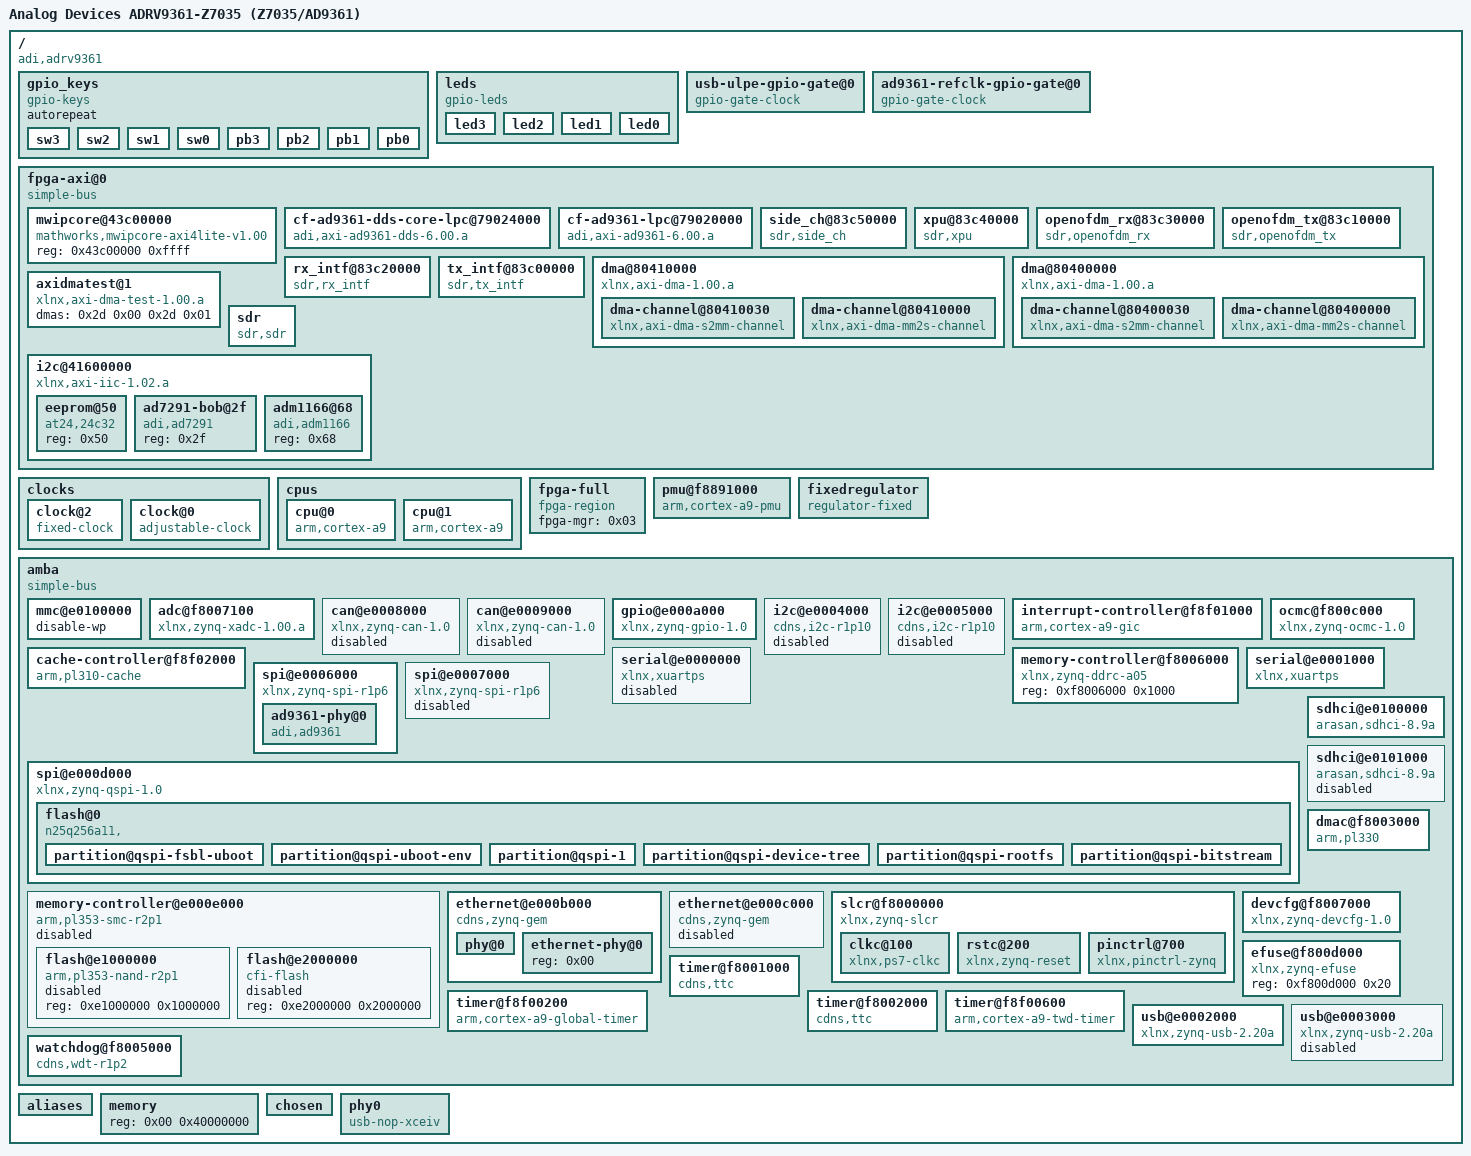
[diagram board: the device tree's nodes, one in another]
/dts-v1/;

/ {
	interrupt-parent = <0x04>;
	#address-cells = <0x01>;
	#size-cells = <0x01>;
	compatible = "adi,adrv9361\0xlnx,zynq-7000";
	model = "Analog Devices ADRV9361-Z7035 (Z7035/AD9361)";

	gpio_keys {
		autorepeat;
		#size-cells = <0x00>;
		#address-cells = <0x01>;
		compatible = "gpio-keys";

		sw3 {
			gpios = <0x0f 0x41 0x00>;
			linux,code = <0x03>;
			linux,input-type = <0x05>;
			label = "SW3";
		};

		sw2 {
			gpios = <0x0f 0x40 0x00>;
			linux,code = <0x02>;
			linux,input-type = <0x05>;
			label = "SW2";
		};

		sw1 {
			gpios = <0x0f 0x3f 0x00>;
			linux,code = <0x01>;
			linux,input-type = <0x05>;
			label = "SW1";
		};

		sw0 {
			gpios = <0x0f 0x3e 0x00>;
			linux,code = <0x00>;
			linux,input-type = <0x05>;
			label = "SW0";
		};

		pb3 {
			gpios = <0x0f 0x39 0x00>;
			linux,code = <0x6c>;
			label = "Down";
		};

		pb2 {
			gpios = <0x0f 0x38 0x00>;
			linux,code = <0x67>;
			label = "Up";
		};

		pb1 {
			gpios = <0x0f 0x37 0x00>;
			linux,code = <0x6a>;
			label = "Right";
		};

		pb0 {
			gpios = <0x0f 0x36 0x00>;
			linux,code = <0x69>;
			label = "Left";
		};
	};

	leds {
		compatible = "gpio-leds";

		led3 {
			gpios = <0x0f 0x3d 0x00>;
			label = "led3:green";
		};

		led2 {
			gpios = <0x0f 0x3c 0x00>;
			label = "led2:green";
		};

		led1 {
			gpios = <0x0f 0x3b 0x00>;
			label = "led1:green";
		};

		led0 {
			gpios = <0x0f 0x3a 0x00>;
			label = "led0:green";
		};
	};

	usb-ulpe-gpio-gate@0 {
		enable-gpios = <0x0f 0x09 0x01>;
		clocks = <0x32>;
		compatible = "gpio-gate-clock";
		#clock-cells = <0x00>;
	};

	ad9361-refclk-gpio-gate@0 {
		phandle = <0x30>;
		clock-output-names = "ad9361_ext_refclk";
		clk-set-rate-parent-enable;
		enable-gpios = <0x0f 0x69 0x00>;
		clocks = <0x31>;
		compatible = "gpio-gate-clock";
		#clock-cells = <0x00>;
	};

	fpga-axi@0 {
		ranges;
		#size-cells = <0x01>;
		#address-cells = <0x01>;
		compatible = "simple-bus";

		mwipcore@43c00000 {
			reg = <0x43c00000 0xffff>;
			compatible = "mathworks,mwipcore-axi4lite-v1.00";
		};

		cf-ad9361-dds-core-lpc@79024000 {
			clock-names = "sampl_clk";
			clocks = <0x2f 0x0d>;
			reg = <0x79024000 0x1000>;
			compatible = "adi,axi-ad9361-dds-6.00.a";
		};

		cf-ad9361-lpc@79020000 {
			spibus-connected = <0x2f>;
			reg = <0x79020000 0x6000>;
			compatible = "adi,axi-ad9361-6.00.a";
		};

		side_ch@83c50000 {
			phandle = <0x3a>;
			dma-names = "rx_dma_mm2s\0tx_dma_s2mm";
			dmas = <0x2d 0x00 0x2e 0x01>;
			reg = <0x83c50000 0x10000>;
			compatible = "sdr,side_ch";
			clocks = <0x2c 0x11>;
			clock-names = "s00_axi_aclk";
		};

		xpu@83c40000 {
			phandle = <0x39>;
			reg = <0x83c40000 0x10000>;
			compatible = "sdr,xpu";
			clocks = <0x2c 0x11>;
			clock-names = "s00_axi_aclk";
		};

		openofdm_rx@83c30000 {
			phandle = <0x38>;
			reg = <0x83c30000 0x10000>;
			compatible = "sdr,openofdm_rx";
			clocks = <0x2c 0x11>;
			clock-names = "clk";
		};

		openofdm_tx@83c10000 {
			phandle = <0x37>;
			reg = <0x83c10000 0x10000>;
			compatible = "sdr,openofdm_tx";
			clocks = <0x2c 0x11>;
			clock-names = "clk";
		};

		rx_intf@83c20000 {
			phandle = <0x36>;
			xlnx,s00-axi-data-width = <0x20>;
			xlnx,s00-axi-addr-width = <0x07>;
			reg = <0x83c20000 0x10000>;
			interrupts = <0x00 0x1d 0x01 0x00 0x1e 0x01>;
			interrupt-parent = <0x04>;
			interrupt-names = "not_valid_anymore\0rx_pkt_intr";
			compatible = "sdr,rx_intf";
			clocks = <0x2c 0x11 0x2c 0x11>;
			clock-names = "s00_axi_aclk\0m00_axis_aclk";
		};

		tx_intf@83c00000 {
			phandle = <0x35>;
			xlnx,s00-axi-data-width = <0x20>;
			xlnx,s00-axi-addr-width = <0x07>;
			reg = <0x83c00000 0x10000>;
			interrupts = <0x00 0x22 0x01>;
			interrupt-parent = <0x04>;
			interrupt-names = "tx_itrpt";
			compatible = "sdr,tx_intf";
			clocks = <0x2c 0x11 0x2c 0x11>;
			clock-names = "s00_axi_aclk\0s00_axis_aclk";
		};

		dma@80410000 {
			phandle = <0x2d>;
			xlnx,sg-length-width = <0x0e>;
			xlnx,include-sg;
			xlnx,addrwidth = <0x20>;
			reg = <0x80410000 0x10000>;
			interrupts = <0x00 0x1f 0x04 0x00 0x20 0x04>;
			interrupt-parent = <0x04>;
			interrupt-names = "mm2s_introut\0s2mm_introut";
			compatible = "xlnx,axi-dma-1.00.a";
			clocks = <0x2c 0x11 0x2c 0x11 0x2c 0x11 0x2c 0x11>;
			clock-names = "s_axi_lite_aclk\0m_axi_sg_aclk\0m_axi_mm2s_aclk\0m_axi_s2mm_aclk";
			#dma-cells = <0x01>;

			dma-channel@80410030 {
				xlnx,device-id = <0x01>;
				xlnx,datawidth = <0x40>;
				interrupts = <0x00 0x20 0x04>;
				dma-channels = <0x01>;
				compatible = "xlnx,axi-dma-s2mm-channel";
			};

			dma-channel@80410000 {
				xlnx,device-id = <0x01>;
				xlnx,datawidth = <0x40>;
				interrupts = <0x00 0x1f 0x04>;
				dma-channels = <0x01>;
				compatible = "xlnx,axi-dma-mm2s-channel";
			};
		};

		dma@80400000 {
			phandle = <0x2e>;
			xlnx,sg-length-width = <0x0e>;
			xlnx,include-sg;
			xlnx,addrwidth = <0x20>;
			reg = <0x80400000 0x10000>;
			interrupts = <0x00 0x23 0x04 0x00 0x24 0x04>;
			interrupt-parent = <0x04>;
			interrupt-names = "mm2s_introut\0s2mm_introut";
			compatible = "xlnx,axi-dma-1.00.a";
			clocks = <0x2c 0x11 0x2c 0x11 0x2c 0x11 0x2c 0x11>;
			clock-names = "s_axi_lite_aclk\0m_axi_sg_aclk\0m_axi_mm2s_aclk\0m_axi_s2mm_aclk";
			#dma-cells = <0x01>;

			dma-channel@80400030 {
				xlnx,device-id = <0x00>;
				xlnx,datawidth = <0x40>;
				interrupts = <0x00 0x24 0x04>;
				dma-channels = <0x01>;
				compatible = "xlnx,axi-dma-s2mm-channel";
			};

			dma-channel@80400000 {
				xlnx,device-id = <0x00>;
				xlnx,datawidth = <0x40>;
				interrupts = <0x00 0x23 0x04>;
				dma-channels = <0x01>;
				compatible = "xlnx,axi-dma-mm2s-channel";
			};
		};

		axidmatest@1 {
			phandle = <0x34>;
			dma-names = "axidma0\0axidma1";
			dmas = <0x2d 0x00 0x2d 0x01>;
			compatible = "xlnx,axi-dma-test-1.00.a";
		};

		sdr {
			phandle = <0x33>;
			interrupts = <0x00 0x1d 0x01 0x00 0x1e 0x01 0x00 0x21 0x01 0x00 0x22 0x01>;
			interrupt-parent = <0x04>;
			interrupt-names = "not_valid_anymore\0rx_pkt_intr\0tx_itrpt";
			dma-names = "rx_dma_s2mm\0tx_dma_mm2s";
			dmas = <0x2d 0x01 0x2e 0x00>;
			compatible = "sdr,sdr";
		};

		i2c@41600000 {
			#size-cells = <0x00>;
			#address-cells = <0x01>;
			clock-names = "pclk";
			clocks = <0x2c 0x0f>;
			interrupts = <0x00 0x3a 0x04>;
			interrupt-parent = <0x04>;
			reg = <0x41600000 0x10000>;
			compatible = "xlnx,axi-iic-1.02.a\0xlnx,xps-iic-2.00.a";

			eeprom@50 {
				reg = <0x50>;
				compatible = "at24,24c32";
			};

			ad7291-bob@2f {
				reg = <0x2f>;
				compatible = "adi,ad7291";
			};

			adm1166@68 {
				reg = <0x68>;
				compatible = "adi,adm1166";
			};
		};
	};

	clocks {

		clock@2 {
			phandle = <0x32>;
			clock-output-names = "24MHz";
			clock-frequency = <0x16e3600>;
			compatible = "fixed-clock";
			#clock-cells = <0x00>;
		};

		clock@0 {
			phandle = <0x31>;
			clock-output-names = "XO_40MHz";
			clock-accuracy = <0x30d40>;
			clock-frequency = <0x2625a00>;
			compatible = "adjustable-clock";
			#clock-cells = <0x00>;
		};
	};

	cpus {
		#address-cells = <0x01>;
		#size-cells = <0x00>;

		cpu@0 {
			compatible = "arm,cortex-a9";
			device_type = "cpu";
			reg = <0x00>;
			clocks = <0x01 0x03>;
			clock-latency = <0x3e8>;
			cpu0-supply = <0x02>;
			operating-points = <0xa2c2b 0xf4240 0x51616 0xf4240>;
			phandle = <0x08>;
		};

		cpu@1 {
			compatible = "arm,cortex-a9";
			device_type = "cpu";
			reg = <0x01>;
			clocks = <0x01 0x03>;
			phandle = <0x09>;
		};
	};

	fpga-full {
		compatible = "fpga-region";
		fpga-mgr = <0x03>;
		#address-cells = <0x01>;
		#size-cells = <0x01>;
		ranges;
		phandle = <0x0a>;
	};

	pmu@f8891000 {
		compatible = "arm,cortex-a9-pmu";
		interrupts = <0x00 0x05 0x04 0x00 0x06 0x04>;
		interrupt-parent = <0x04>;
		reg = <0xf8891000 0x1000 0xf8893000 0x1000>;
	};

	fixedregulator {
		compatible = "regulator-fixed";
		regulator-name = "VCCPINT";
		regulator-min-microvolt = <0xf4240>;
		regulator-max-microvolt = <0xf4240>;
		regulator-boot-on;
		regulator-always-on;
		phandle = <0x02>;
	};

	amba {
		u-boot,dm-pre-reloc;
		compatible = "simple-bus";
		#address-cells = <0x01>;
		#size-cells = <0x01>;
		interrupt-parent = <0x04>;
		ranges;
		phandle = <0x0b>;

		mmc@e0100000 {
			phandle = <0x3c>;
			disable-wp;
		};

		adc@f8007100 {
			compatible = "xlnx,zynq-xadc-1.00.a";
			reg = <0xf8007100 0x20>;
			interrupts = <0x00 0x07 0x04>;
			interrupt-parent = <0x04>;
			clocks = <0x01 0x0c>;
			phandle = <0x0c>;
		};

		can@e0008000 {
			compatible = "xlnx,zynq-can-1.0";
			status = "disabled";
			clocks = <0x01 0x13 0x01 0x24>;
			clock-names = "can_clk\0pclk";
			reg = <0xe0008000 0x1000>;
			interrupts = <0x00 0x1c 0x04>;
			interrupt-parent = <0x04>;
			tx-fifo-depth = <0x40>;
			rx-fifo-depth = <0x40>;
			phandle = <0x0d>;
		};

		can@e0009000 {
			compatible = "xlnx,zynq-can-1.0";
			status = "disabled";
			clocks = <0x01 0x14 0x01 0x25>;
			clock-names = "can_clk\0pclk";
			reg = <0xe0009000 0x1000>;
			interrupts = <0x00 0x33 0x04>;
			interrupt-parent = <0x04>;
			tx-fifo-depth = <0x40>;
			rx-fifo-depth = <0x40>;
			phandle = <0x0e>;
		};

		gpio@e000a000 {
			compatible = "xlnx,zynq-gpio-1.0";
			#gpio-cells = <0x02>;
			clocks = <0x01 0x2a>;
			gpio-controller;
			interrupt-controller;
			#interrupt-cells = <0x02>;
			interrupt-parent = <0x04>;
			interrupts = <0x00 0x14 0x04>;
			reg = <0xe000a000 0x1000>;
			phandle = <0x0f>;
		};

		i2c@e0004000 {
			compatible = "cdns,i2c-r1p10";
			status = "disabled";
			clocks = <0x01 0x26>;
			interrupt-parent = <0x04>;
			interrupts = <0x00 0x19 0x04>;
			reg = <0xe0004000 0x1000>;
			#address-cells = <0x01>;
			#size-cells = <0x00>;
			phandle = <0x10>;
		};

		i2c@e0005000 {
			compatible = "cdns,i2c-r1p10";
			status = "disabled";
			clocks = <0x01 0x27>;
			interrupt-parent = <0x04>;
			interrupts = <0x00 0x30 0x04>;
			reg = <0xe0005000 0x1000>;
			#address-cells = <0x01>;
			#size-cells = <0x00>;
			phandle = <0x11>;
		};

		interrupt-controller@f8f01000 {
			compatible = "arm,cortex-a9-gic";
			#interrupt-cells = <0x03>;
			interrupt-controller;
			reg = <0xf8f01000 0x1000 0xf8f00100 0x100>;
			phandle = <0x04>;
		};

		cache-controller@f8f02000 {
			compatible = "arm,pl310-cache";
			reg = <0xf8f02000 0x1000>;
			interrupts = <0x00 0x02 0x04>;
			arm,data-latency = <0x03 0x02 0x02>;
			arm,tag-latency = <0x02 0x02 0x02>;
			cache-unified;
			cache-level = <0x02>;
			phandle = <0x12>;
		};

		memory-controller@f8006000 {
			compatible = "xlnx,zynq-ddrc-a05";
			reg = <0xf8006000 0x1000>;
			phandle = <0x13>;
		};

		ocmc@f800c000 {
			compatible = "xlnx,zynq-ocmc-1.0";
			interrupt-parent = <0x04>;
			interrupts = <0x00 0x03 0x04>;
			reg = <0xf800c000 0x1000>;
			phandle = <0x14>;
		};

		serial@e0000000 {
			compatible = "xlnx,xuartps\0cdns,uart-r1p8";
			status = "disabled";
			clocks = <0x01 0x17 0x01 0x28>;
			clock-names = "uart_clk\0pclk";
			reg = <0xe0000000 0x1000>;
			interrupts = <0x00 0x1b 0x04>;
			phandle = <0x15>;
		};

		serial@e0001000 {
			compatible = "xlnx,xuartps\0cdns,uart-r1p8";
			status = "okay";
			clocks = <0x01 0x18 0x01 0x29>;
			clock-names = "uart_clk\0pclk";
			reg = <0xe0001000 0x1000>;
			interrupts = <0x00 0x32 0x04>;
			phandle = <0x16>;
		};

		spi@e0006000 {
			compatible = "xlnx,zynq-spi-r1p6";
			reg = <0xe0006000 0x1000>;
			status = "okay";
			interrupt-parent = <0x04>;
			interrupts = <0x00 0x1a 0x04>;
			clocks = <0x01 0x19 0x01 0x22>;
			clock-names = "ref_clk\0pclk";
			#address-cells = <0x01>;
			#size-cells = <0x00>;
			phandle = <0x3b>;

			ad9361-phy@0 {
				phandle = <0x2f>;
				txnrx-gpios = <0x0f 0x66 0x00>;
				enable-gpios = <0x0f 0x65 0x00>;
				reset-gpios = <0x0f 0x64 0x00>;
				sync-gpios = <0x0f 0x63 0x00>;
				en_agc-gpios = <0x0f 0x62 0x00>;
				adi,aux-dac2-tx-delay-us = <0x00>;
				adi,aux-dac2-rx-delay-us = <0x00>;
				adi,aux-dac2-default-value-mV = <0x00>;
				adi,aux-dac1-tx-delay-us = <0x00>;
				adi,aux-dac1-rx-delay-us = <0x00>;
				adi,aux-dac1-default-value-mV = <0x00>;
				adi,aux-dac-manual-mode-enable;
				adi,temp-sense-periodic-measurement-enable;
				adi,temp-sense-offset-signed = <0xce>;
				adi,temp-sense-measurement-interval-ms = <0x3e8>;
				adi,ctrl-outs-enable-mask = <0xff>;
				adi,ctrl-outs-index = <0x00>;
				adi,rssi-duration = <0x3e8>;
				adi,rssi-wait = <0x01>;
				adi,rssi-delay = <0x01>;
				adi,rssi-restart-mode = <0x03>;
				adi,fagc-use-last-lock-level-for-set-gain-enable;
				adi,fagc-state-wait-time-ns = <0x104>;
				adi,fagc-rst-gla-stronger-sig-thresh-above-ll = <0x0a>;
				adi,fagc-rst-gla-large-lmt-overload-enable;
				adi,fagc-rst-gla-large-adc-overload-enable;
				adi,fagc-rst-gla-if-en-agc-pulled-high-mode = <0x00>;
				adi,fagc-rst-gla-engergy-lost-sig-thresh-below-ll = <0x0a>;
				adi,fagc-rst-gla-engergy-lost-goto-optim-gain-enable;
				adi,fagc-power-measurement-duration-in-state5 = <0x10>;
				adi,fagc-optimized-gain-offset = <0x05>;
				adi,fagc-lpf-final-settling-steps = <0x01>;
				adi,fagc-lock-level-lmt-gain-increase-enable;
				adi,fagc-lock-level-gain-increase-upper-limit = <0x05>;
				adi,fagc-lock-level = <0x0a>;
				adi,fagc-lmt-final-settling-steps = <0x01>;
				adi,fagc-gain-index-type-after-exit-rx-mode = <0x00>;
				adi,fagc-final-overrange-count = <0x03>;
				adi,fagc-dig-sat-ovrg-enable;
				adi,fagc-energy-lost-stronger-sig-gain-lock-exit-cnt = <0x08>;
				adi,fagc-lp-thresh-increment-time = <0x05>;
				adi,fagc-lp-thresh-increment-steps = <0x01>;
				adi,fagc-adc-large-overload-inc-steps = <0x07>;
				adi,fagc-dec-pow-measurement-duration = <0x10>;
				adi,agc-gain-update-interval-us = <0x3e8>;
				adi,agc-lmt-overload-large-inc-steps = <0x07>;
				adi,agc-lmt-overload-small-exceed-counter = <0x0a>;
				adi,agc-lmt-overload-large-exceed-counter = <0x0a>;
				adi,agc-adc-large-overload-inc-steps = <0x07>;
				adi,agc-adc-large-overload-exceed-counter = <0x0a>;
				adi,agc-adc-small-overload-exceed-counter = <0x0a>;
				adi,agc-outer-thresh-low-inc-steps = <0x02>;
				adi,agc-outer-thresh-low = <0x12>;
				adi,agc-inner-thresh-low-inc-steps = <0x01>;
				adi,agc-inner-thresh-low = <0x0c>;
				adi,agc-inner-thresh-high-dec-steps = <0x01>;
				adi,agc-inner-thresh-high = <0x0a>;
				adi,agc-outer-thresh-high-dec-steps = <0x02>;
				adi,agc-outer-thresh-high = <0x05>;
				adi,agc-attack-delay-extra-margin-us = <0x01>;
				adi,mgc-split-table-ctrl-inp-gain-mode = <0x00>;
				adi,mgc-dec-gain-step = <0x02>;
				adi,mgc-inc-gain-step = <0x02>;
				adi,gc-low-power-thresh = <0x18>;
				adi,gc-dec-pow-measurement-duration = <0x2000>;
				adi,gc-lmt-overload-low-thresh = <0x2c0>;
				adi,gc-lmt-overload-high-thresh = <0x320>;
				adi,gc-adc-large-overload-thresh = <0x3a>;
				adi,gc-adc-small-overload-thresh = <0x2f>;
				adi,gc-adc-ovr-sample-size = <0x04>;
				adi,gc-rx2-mode = <0x02>;
				adi,gc-rx1-mode = <0x02>;
				adi,tx-path-clock-frequencies = <0x3a980000 0x7530000 0x7530000 0x3a98000 0x1d4c000 0x1d4c000>;
				adi,rx-path-clock-frequencies = <0x3a980000 0xea60000 0x7530000 0x3a98000 0x1d4c000 0x1d4c000>;
				adi,tx-synthesizer-frequency-hz = <0x00 0x92080880>;
				adi,rx-synthesizer-frequency-hz = <0x00 0x8f0d1800>;
				adi,rf-tx-bandwidth-hz = <0x112a880>;
				adi,rf-rx-bandwidth-hz = <0x112a880>;
				adi,tx-lo-powerdown-managed-enable;
				adi,tx-attenuation-mdB = <0x2710>;
				adi,tx-rf-port-input-select = <0x00>;
				adi,rx-rf-port-input-select = <0x00>;
				adi,frequency-division-duplex-mode-enable;
				adi,2rx-2tx-mode-enable;
				adi,xo-disable-use-ext-refclk-enable;
				adi,tx-fb-clock-delay = <0x07>;
				adi,rx-data-delay = <0x04>;
				adi,lvds-rx-onchip-termination-enable;
				adi,lvds-bias-mV = <0x96>;
				adi,lvds-mode-enable;
				adi,rx-frame-pulse-mode-enable;
				adi,pp-rx-swap-enable;
				adi,pp-tx-swap-enable;
				adi,digital-interface-tune-skip-mode = <0x00>;
				clock-output-names = "rx_sampl_clk\0tx_sampl_clk";
				clock-names = "ad9361_ext_refclk";
				clocks = <0x30 0x00>;
				spi-max-frequency = <0x989680>;
				spi-cpha;
				reg = <0x00>;
				compatible = "adi,ad9361";
				#clock-cells = <0x01>;
				#size-cells = <0x00>;
				#address-cells = <0x01>;
			};
		};

		spi@e0007000 {
			compatible = "xlnx,zynq-spi-r1p6";
			reg = <0xe0007000 0x1000>;
			status = "disabled";
			interrupt-parent = <0x04>;
			interrupts = <0x00 0x31 0x04>;
			clocks = <0x01 0x1a 0x01 0x23>;
			clock-names = "ref_clk\0pclk";
			#address-cells = <0x01>;
			#size-cells = <0x00>;
			phandle = <0x18>;
		};

		spi@e000d000 {
			clock-names = "ref_clk\0pclk";
			clocks = <0x01 0x0a 0x01 0x2b>;
			compatible = "xlnx,zynq-qspi-1.0";
			status = "okay";
			interrupt-parent = <0x04>;
			interrupts = <0x00 0x13 0x04>;
			reg = <0xe000d000 0x1000>;
			#address-cells = <0x01>;
			#size-cells = <0x00>;
			is-dual = <0x00>;
			num-cs = <0x01>;
			phandle = <0x19>;

			flash@0 {
				compatible = "n25q256a11,";
				reg = <0x00>;
				spi-tx-bus-width = <0x01>;
				spi-rx-bus-width = <0x04>;
				spi-max-frequency = <0x2faf080>;
				#address-cells = <0x01>;
				#size-cells = <0x01>;

				partition@qspi-fsbl-uboot {
					label = "qspi-fsbl-uboot";
					reg = <0x00 0xe0000>;
				};

				partition@qspi-uboot-env {
					label = "qspi-uboot-env";
					reg = <0xe0000 0x20000>;
				};

				partition@qspi-1 {
					label = "qspi-linux";
					reg = <0x100000 0x500000>;
				};

				partition@qspi-device-tree {
					label = "qspi-device-tree";
					reg = <0x600000 0x20000>;
				};

				partition@qspi-rootfs {
					label = "qspi-rootfs";
					reg = <0x620000 0xce0000>;
				};

				partition@qspi-bitstream {
					label = "qspi-bitstream";
					reg = <0x1300000 0xd00000>;
				};
			};
		};

		memory-controller@e000e000 {
			#address-cells = <0x01>;
			#size-cells = <0x01>;
			status = "disabled";
			clock-names = "memclk\0aclk";
			clocks = <0x01 0x0b 0x01 0x2c>;
			compatible = "arm,pl353-smc-r2p1";
			interrupt-parent = <0x04>;
			interrupts = <0x00 0x12 0x04>;
			ranges;
			reg = <0xe000e000 0x1000>;
			phandle = <0x1a>;

			flash@e1000000 {
				status = "disabled";
				compatible = "arm,pl353-nand-r2p1";
				reg = <0xe1000000 0x1000000>;
				#address-cells = <0x01>;
				#size-cells = <0x01>;
				phandle = <0x1b>;
			};

			flash@e2000000 {
				status = "disabled";
				compatible = "cfi-flash";
				reg = <0xe2000000 0x2000000>;
				#address-cells = <0x01>;
				#size-cells = <0x01>;
				phandle = <0x1c>;
			};
		};

		ethernet@e000b000 {
			compatible = "cdns,zynq-gem\0cdns,gem";
			reg = <0xe000b000 0x1000>;
			status = "okay";
			interrupts = <0x00 0x16 0x04>;
			clocks = <0x01 0x1e 0x01 0x1e 0x01 0x0d>;
			clock-names = "pclk\0hclk\0tx_clk";
			#address-cells = <0x01>;
			#size-cells = <0x00>;
			phy-mode = "rgmii-id";
			phy-handle = <0x3f>;
			phandle = <0x1d>;

			phy@0 {
				phandle = <0x3f>;
				marvell,reg-init = <0x03 0x10 0xff00 0x1e 0x03 0x11 0xfff0 0x00>;
				reg = <0x00>;
				device_type = "ethernet-phy";
			};

			ethernet-phy@0 {
				reg = <0x00>;
				phandle = <0x05>;
			};
		};

		ethernet@e000c000 {
			compatible = "cdns,zynq-gem\0cdns,gem";
			reg = <0xe000c000 0x1000>;
			status = "disabled";
			interrupts = <0x00 0x2d 0x04>;
			clocks = <0x01 0x1f 0x01 0x1f 0x01 0x0e>;
			clock-names = "pclk\0hclk\0tx_clk";
			#address-cells = <0x01>;
			#size-cells = <0x00>;
			phandle = <0x1e>;
		};

		sdhci@e0100000 {
			compatible = "arasan,sdhci-8.9a";
			status = "okay";
			clock-names = "clk_xin\0clk_ahb";
			clocks = <0x01 0x15 0x01 0x20>;
			interrupt-parent = <0x04>;
			interrupts = <0x00 0x18 0x04>;
			reg = <0xe0100000 0x1000>;
			phandle = <0x1f>;
		};

		sdhci@e0101000 {
			compatible = "arasan,sdhci-8.9a";
			status = "disabled";
			clock-names = "clk_xin\0clk_ahb";
			clocks = <0x01 0x16 0x01 0x21>;
			interrupt-parent = <0x04>;
			interrupts = <0x00 0x2f 0x04>;
			reg = <0xe0101000 0x1000>;
			phandle = <0x20>;
		};

		slcr@f8000000 {
			u-boot,dm-pre-reloc;
			#address-cells = <0x01>;
			#size-cells = <0x01>;
			compatible = "xlnx,zynq-slcr\0syscon\0simple-mfd";
			reg = <0xf8000000 0x1000>;
			ranges;
			phandle = <0x3d>;

			clkc@100 {
				ps-clk-frequency = <0x1fca055>;
				u-boot,dm-pre-reloc;
				#clock-cells = <0x01>;
				compatible = "xlnx,ps7-clkc";
				fclk-enable = <0x0f>;
				clock-output-names = "armpll\0ddrpll\0iopll\0cpu_6or4x\0cpu_3or2x\0cpu_2x\0cpu_1x\0ddr2x\0ddr3x\0dci\0lqspi\0smc\0pcap\0gem0\0gem1\0fclk0\0fclk1\0fclk2\0fclk3\0can0\0can1\0sdio0\0sdio1\0uart0\0uart1\0spi0\0spi1\0dma\0usb0_aper\0usb1_aper\0gem0_aper\0gem1_aper\0sdio0_aper\0sdio1_aper\0spi0_aper\0spi1_aper\0can0_aper\0can1_aper\0i2c0_aper\0i2c1_aper\0uart0_aper\0uart1_aper\0gpio_aper\0lqspi_aper\0smc_aper\0swdt\0dbg_trc\0dbg_apb";
				reg = <0x100 0x100>;
				phandle = <0x2c>;
			};

			rstc@200 {
				compatible = "xlnx,zynq-reset";
				reg = <0x200 0x48>;
				#reset-cells = <0x01>;
				syscon = <0x06>;
				phandle = <0x21>;
			};

			pinctrl@700 {
				compatible = "xlnx,pinctrl-zynq";
				reg = <0x700 0x200>;
				syscon = <0x06>;
				phandle = <0x22>;
			};
		};

		dmac@f8003000 {
			compatible = "arm,pl330\0arm,primecell";
			reg = <0xf8003000 0x1000>;
			interrupt-parent = <0x04>;
			interrupt-names = "abort\0dma0\0dma1\0dma2\0dma3\0dma4\0dma5\0dma6\0dma7";
			interrupts = <0x00 0x0d 0x04 0x00 0x0e 0x04 0x00 0x0f 0x04 0x00 0x10 0x04 0x00 0x11 0x04 0x00 0x28 0x04 0x00 0x29 0x04 0x00 0x2a 0x04 0x00 0x2b 0x04>;
			#dma-cells = <0x01>;
			#dma-channels = <0x08>;
			#dma-requests = <0x04>;
			clocks = <0x01 0x1b>;
			clock-names = "apb_pclk";
			phandle = <0x23>;
		};

		devcfg@f8007000 {
			compatible = "xlnx,zynq-devcfg-1.0";
			interrupt-parent = <0x04>;
			interrupts = <0x00 0x08 0x04>;
			reg = <0xf8007000 0x100>;
			clocks = <0x01 0x0c 0x01 0x0f 0x01 0x10 0x01 0x11 0x01 0x12>;
			clock-names = "ref_clk\0fclk0\0fclk1\0fclk2\0fclk3";
			syscon = <0x06>;
			phandle = <0x03>;
		};

		efuse@f800d000 {
			compatible = "xlnx,zynq-efuse";
			reg = <0xf800d000 0x20>;
			phandle = <0x24>;
		};

		timer@f8f00200 {
			compatible = "arm,cortex-a9-global-timer";
			reg = <0xf8f00200 0x20>;
			interrupts = <0x01 0x0b 0x301>;
			interrupt-parent = <0x04>;
			clocks = <0x01 0x04>;
			phandle = <0x25>;
		};

		timer@f8001000 {
			interrupt-parent = <0x04>;
			interrupts = <0x00 0x0a 0x04 0x00 0x0b 0x04 0x00 0x0c 0x04>;
			compatible = "cdns,ttc";
			clocks = <0x01 0x06>;
			reg = <0xf8001000 0x1000>;
			phandle = <0x26>;
		};

		timer@f8002000 {
			interrupt-parent = <0x04>;
			interrupts = <0x00 0x25 0x04 0x00 0x26 0x04 0x00 0x27 0x04>;
			compatible = "cdns,ttc";
			clocks = <0x01 0x06>;
			reg = <0xf8002000 0x1000>;
			phandle = <0x27>;
		};

		timer@f8f00600 {
			interrupt-parent = <0x04>;
			interrupts = <0x01 0x0d 0x301>;
			compatible = "arm,cortex-a9-twd-timer";
			reg = <0xf8f00600 0x20>;
			clocks = <0x01 0x04>;
			phandle = <0x28>;
		};

		usb@e0002000 {
			xlnx,phy-reset-gpio = <0x06 0x07 0x00>;
			compatible = "xlnx,zynq-usb-2.20a\0chipidea,usb2";
			status = "okay";
			clocks = <0x01 0x1c>;
			interrupt-parent = <0x04>;
			interrupts = <0x00 0x15 0x04>;
			reg = <0xe0002000 0x1000>;
			phy_type = "ulpi";
			dr_mode = "host";
			usb-phy = <0x07>;
			phandle = <0x3e>;
		};

		usb@e0003000 {
			compatible = "xlnx,zynq-usb-2.20a\0chipidea,usb2";
			status = "disabled";
			clocks = <0x01 0x1d>;
			interrupt-parent = <0x04>;
			interrupts = <0x00 0x2c 0x04>;
			reg = <0xe0003000 0x1000>;
			phy_type = "ulpi";
			phandle = <0x2a>;
		};

		watchdog@f8005000 {
			clocks = <0x01 0x2d>;
			compatible = "cdns,wdt-r1p2";
			interrupt-parent = <0x04>;
			interrupts = <0x00 0x09 0x01>;
			reg = <0xf8005000 0x1000>;
			timeout-sec = <0x0a>;
			phandle = <0x2b>;
		};
	};

	aliases {
		ethernet0 = "/amba/ethernet@e000b000";
		serial0 = "/amba/serial@e0001000";
		spi0 = "/amba/spi@e000d000";
	};

	memory {
		device_type = "memory";
		reg = <0x00 0x40000000>;
	};

	chosen {
		bootargs = "earlyprintk";
		1,stdout-path = "/amba/serial@e0001000";
		stdout-path = "/amba/serial@e0001000";
	};

	phy0 {
		compatible = "usb-nop-xceiv";
		#phy-cells = <0x00>;
		phandle = <0x07>;
	};

	__symbols__ {
		phy0 = "/amba/ethernet@e000b000/phy@0";
		gated_40M_ad9361_clk = "/ad9361-refclk-gpio-gate@0";
		ad9361_phy = "/amba/spi@e0006000/ad9361-phy@0";
		side_ch_0 = "/fpga-axi@0/side_ch@83c50000";
		xpu_0 = "/fpga-axi@0/xpu@83c40000";
		openofdm_rx_0 = "/fpga-axi@0/openofdm_rx@83c30000";
		openofdm_tx_0 = "/fpga-axi@0/openofdm_tx@83c10000";
		rx_intf_0 = "/fpga-axi@0/rx_intf@83c20000";
		tx_intf_0 = "/fpga-axi@0/tx_intf@83c00000";
		rx_dma = "/fpga-axi@0/dma@80410000";
		tx_dma = "/fpga-axi@0/dma@80400000";
		axidmatest_1 = "/fpga-axi@0/axidmatest@1";
		sdr = "/fpga-axi@0/sdr";
		clk_24M_fixed = "/clocks/clock@2";
		clk_40M_adj = "/clocks/clock@0";
		cpu0 = "/cpus/cpu@0";
		cpu1 = "/cpus/cpu@1";
		fpga_full = "/fpga-full";
		regulator_vccpint = "/fixedregulator";
		amba = "/amba";
		adc = "/amba/adc@f8007100";
		can0 = "/amba/can@e0008000";
		can1 = "/amba/can@e0009000";
		gpio0 = "/amba/gpio@e000a000";
		i2c0 = "/amba/i2c@e0004000";
		i2c1 = "/amba/i2c@e0005000";
		intc = "/amba/interrupt-controller@f8f01000";
		L2 = "/amba/cache-controller@f8f02000";
		mc = "/amba/memory-controller@f8006000";
		ocmc = "/amba/ocmc@f800c000";
		uart0 = "/amba/serial@e0000000";
		uart1 = "/amba/serial@e0001000";
		spi0 = "/amba/spi@e0006000";
		spi1 = "/amba/spi@e0007000";
		qspi = "/amba/spi@e000d000";
		smcc = "/amba/memory-controller@e000e000";
		nand0 = "/amba/memory-controller@e000e000/flash@e1000000";
		nor0 = "/amba/memory-controller@e000e000/flash@e2000000";
		gem0 = "/amba/ethernet@e000b000";
		ethernet_phy = "/amba/ethernet@e000b000/ethernet-phy@0";
		gem1 = "/amba/ethernet@e000c000";
		sdhci0 = "/amba/mmc@e0100000";
		sdhci1 = "/amba/sdhci@e0101000";
		slcr = "/amba/slcr@f8000000";
		clkc = "/amba/slcr@f8000000/clkc@100";
		rstc = "/amba/slcr@f8000000/rstc@200";
		pinctrl0 = "/amba/slcr@f8000000/pinctrl@700";
		dmac_s = "/amba/dmac@f8003000";
		devcfg = "/amba/devcfg@f8007000";
		efuse = "/amba/efuse@f800d000";
		global_timer = "/amba/timer@f8f00200";
		ttc0 = "/amba/timer@f8001000";
		ttc1 = "/amba/timer@f8002000";
		scutimer = "/amba/timer@f8f00600";
		usb0 = "/amba/usb@e0002000";
		usb1 = "/amba/usb@e0003000";
		watchdog0 = "/amba/watchdog@f8005000";
		usb_phy0 = "/phy0";
	};
};
